# M261_v1 register map
File version: 1.0
Registers are 32-bit, read-write, reset 0x0 unless marked. A register's access mark holds for its fields unless they carry their own. Offsets are from the block's base; [hi:lo] are bit positions.

## TRNG — TRNG Register Map
Base 0x400B9000
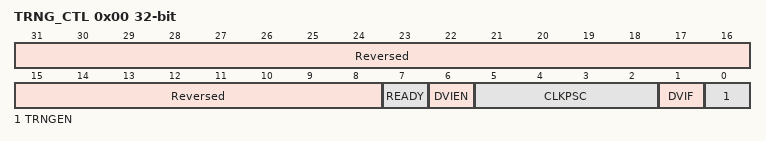
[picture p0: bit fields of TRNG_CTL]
0x00 TRNG_CTL — TRNG Control Register and Status
  [31:8] Reversed
  [7] READY ro — Random Number Generator Ready (Read Only). After ACT (TRNG_ACT[7]) bit is set, the READY bit become to 1 after a delay of 90us~120us.
    0=RNG is not ready or was not activated; 1=RNG is ready to be enabled
  [6] DVIEN — Data Valid Interrupt Enable Bit
    0=Interrupt Disabled; 1=Interrupt Enabled
  [5:2] CLKPSC — Clock Prescaler. The CLKPSC is the peripheral clock frequency range for the selected value , the CLKPSC setting must be higher than or equal to the actual peripheral clock frequency (for correct random bit generation). To change the CLKPSC setting, set TRNGEN bit to 0, change CLKPSC, and set TRNGEN bit to 1 to re-enable the TRNG.
    0=80 ~ 100 MHz; 1=60 ~ 80 MHz; 2=50 ~60 MHz; 3=40 ~50 MHz; 4=30 ~40 MHz; 5=25 ~30 MHz; 6=20 ~25 MHz; 7=15 ~20 MHz; 8=12 ~15 MHz; 9=9 ~12 MHz; 10=7 ~9 MHz; 11=6 ~7 MHz; 12=5 ~6 MHz; 13=4 ~5 MHz
  [1] DVIF ro — Data Valid (Read Only). This bit is cleared to '0' by read TRNG_DATA.
    0=Data is not valid. Reading from RNGD returns 0x00000000; 1=Data is valid. A valid random number can be read form RNGD
  [0] TRNGEN — Random Number Generator Enable Bit. This bit can be set to 1 only after ACT (TRNG_ACT[7]) bit was set to 1 and READY (TRNG_CTL[7]) bit became 1. Note: TRNGEN is an enable bit of digital part. When TRNG is not required to generate random number, TRNGEN bit and ACT (TRNG_ACT[7]) bit should be set to 0 to reduce power consumption.
    0=TRNG Disabled; 1=TRNG Enabled
0x04 TRNG_DATA ro
  [7:0] DATA — Random Number Generator Data (Read Only). The DATA store the random number generated by TRNG and can be read only once.
0x0C TRNG_ACT reset 0x2 — TRNG Activation Register
  [7] ACT — Random Number Generator Activation. After enable the ACT bit, it will active the TRNG module and wait the READY (TRNG_CTL[7]) bit to become 1. Note: ACT is an enable bit of analog part. When TRNG is not required to generate random number, TRNGEN (TRNG_CTL[0]) bit and ACT bit should be set to 0 to reduce power consumption.
    0=TRNG inactive; 1=TRNG active

## WWDT — WWDT Register Map
Base 0x40040100
0x00 WWDT_RLDCNT wo — WWDT Reload Counter Register
  [31:0] RLDCNT — WWDT Reload Counter Register. Writing 0x00005AA5 to this register will reload the WWDT counter value to 0x3F. Note: User can only write WWDT_RLDCNT register to reload WWDT counter value when current WWDT counter value between 0 and CMPDAT (WWDT_CTL[21:16]). If user writes WWDT_RLDCNT when current WWDT counter value is larger than CMPDAT, WWDT reset signal will be generated immediately.
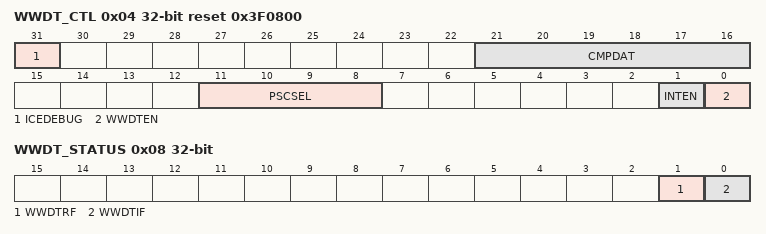
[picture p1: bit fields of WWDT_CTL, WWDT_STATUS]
0x04 WWDT_CTL reset 0x3F0800 — WWDT Control Register
  [31] ICEDEBUG — ICE Debug Mode Acknowledge Disable Bit. WWDT down counter will keep going no matter CPU is held by ICE or not.
    0=ICE debug mode acknowledgement effects WWDT counting; 1=ICE debug mode acknowledgement Disabled
  [21:16] CMPDAT — WWDT Window Compare Register. Set this register to adjust the valid reload window. Note: User can only write WWDT_RLDCNT register to reload WWDT counter value when current WWDT counter value between 0 and CMPDAT. If user writes WWDT_RLDCNT register when current WWDT counter value larger than CMPDAT, WWDT reset signal will generate immediately.
  [11:8] PSCSEL — WWDT Counter Prescale Period Selection
    0=Pre-scale is 1; Max time-out period is 1 * 64 * WWDT_CLK; 1=Pre-scale is 2; Max time-out period is 2 * 64 * WWDT_CLK; 2=Pre-scale is 4; Max time-out period is 4 * 64 * WWDT_CLK; 3=Pre-scale is 8; Max time-out period is 8 * 64 * WWDT_CLK; 4=Pre-scale is 16; Max time-out period is 16 * 64 * WWDT_CLK; 5=Pre-scale is 32; Max time-out period is 32 * 64 * WWDT_CLK; 6=Pre-scale is 64; Max time-out period is 64 * 64 * WWDT_CLK; 7=Pre-scale is 128; Max time-out period is 128 * 64 * WWDT_CLK; 8=Pre-scale is 192; Max time-out period is 192 * 64 * WWDT_CLK; 9=Pre-scale is 256; Max time-out period is 256 * 64 * WWDT_CLK; 10=Pre-scale is 384; Max time-out period is 384 * 64 * WWDT_CLK; 11=Pre-scale is 512; Max time-out period is 512 * 64 * WWDT_CLK; 12=Pre-scale is 768; Max time-out period is 768 * 64 * WWDT_CLK; 13=Pre-scale is 1024; Max time-out period is 1024 * 64 * WWDT_CLK; 14=Pre-scale is 1536; Max time-out period is 1536 * 64 * WWDT_CLK; 15=Pre-scale is 2048; Max time-out period is 2048 * 64 * WWDT_CLK
  [1] INTEN — WWDT Interrupt Enable Bit. If this bit is enabled, the WWDT counter compare match interrupt signal is generated and inform to CPU.
    0=WWDT counter compare match interrupt Disabled; 1=WWDT counter compare match interrupt Enabled
  [0] WWDTEN — WWDT Enable Bit
    0=WWDT counter is stopped; 1=WWDT counter starts counting
0x08 WWDT_STATUS
  [1] WWDTRF — WWDT Timer-out Reset Flag. This bit indicates the system has been reset by WWDT time-out reset or not. Note: This bit is cleared by writing 1 to it.
    0=WWDT time-out reset did not occur; 1=WWDT time-out reset occurred
  [0] WWDTIF — WWDT Compare Match Interrupt Flag. This bit indicates the interrupt flag status of WWDT while WWDT counter value matches CMPDAT (WWDT_CTL[21:16]). Note: This bit is cleared by writing 1 to it.
    0=No effect; 1=WWDT counter value matches CMPDAT
0x0C WWDT_CNT ro reset 0x3F — WWDT Counter Value Register
  [5:0] CNTDAT — WWDT Counter Value. CNTDAT will be updated continuously to monitor 6-bit WWDT down counter value.
